AUTOSAR XML (schema 4-0-3)
package /ComponentTypes
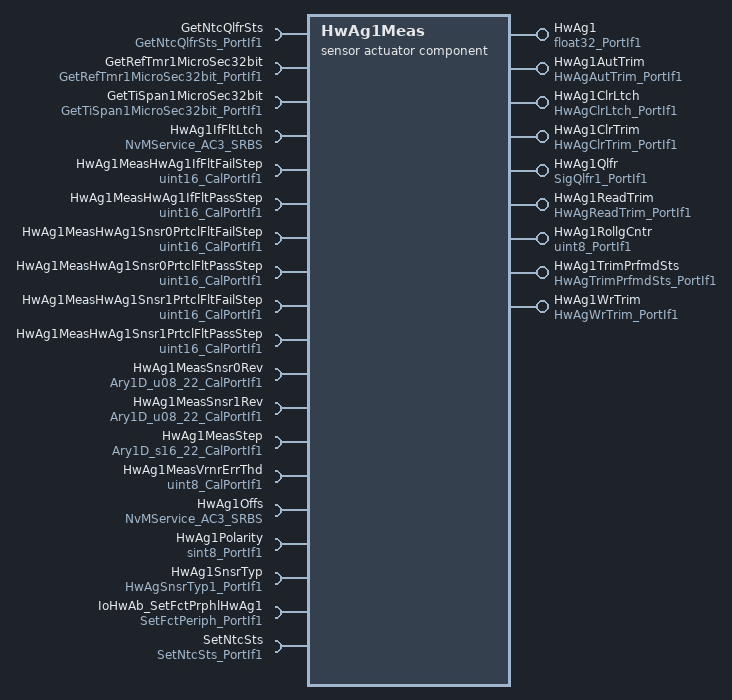
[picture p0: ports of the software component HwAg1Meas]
  sensor actuator sw component type HwAg1Meas
    9 x provide port:
      HwAg1: nonqueued-sender-com-spec{data-element=Val, init-value=0}, provided-interface=float32_PortIf1
      HwAg1AutTrim: server-com-spec{operation=Oper, queue-length=1}, provided-interface=HwAgAutTrim_PortIf1
      HwAg1ClrLtch: server-com-spec{operation=Oper, queue-length=1}, provided-interface=HwAgClrLtch_PortIf1
      HwAg1ClrTrim: server-com-spec{operation=Oper, queue-length=1}, provided-interface=HwAgClrTrim_PortIf1
      HwAg1Qlfr: nonqueued-sender-com-spec{data-element=Val, init-value=0}, provided-interface=SigQlfr1_PortIf1
      HwAg1ReadTrim: server-com-spec{operation=Oper, queue-length=1}, provided-interface=HwAgReadTrim_PortIf1
      HwAg1RollgCntr: nonqueued-sender-com-spec{data-element=Val, init-value=0}, provided-interface=uint8_PortIf1
      HwAg1TrimPrfmdSts: server-com-spec{operation=Oper, queue-length=1}, provided-interface=HwAgTrimPrfmdSts_PortIf1
      HwAg1WrTrim: server-com-spec{operation=Oper, queue-length=1}, provided-interface=HwAgWrTrim_PortIf1
    19 x require port:
      GetNtcQlfrSts: client-com-spec=Oper, required-interface=GetNtcQlfrSts_PortIf1
      GetRefTmr1MicroSec32bit: client-com-spec=Oper, required-interface=GetRefTmr1MicroSec32bit_PortIf1
      GetTiSpan1MicroSec32bit: client-com-spec=Oper, required-interface=GetTiSpan1MicroSec32bit_PortIf1
      HwAg1IfFltLtch: required-com-specs=[EraseBlock, GetErrorStatus, InvalidateNvBlock, ReadBlock, SetRamBlockStatus, WriteBlock], required-interface=NvMService_AC3_SRBS
      HwAg1MeasHwAg1IfFltFailStep: parameter-require-com-spec{init-value=2521, parameter=Val}, required-interface=uint16_CalPortIf1
      HwAg1MeasHwAg1IfFltPassStep: parameter-require-com-spec{init-value=1000, parameter=Val}, required-interface=uint16_CalPortIf1
      HwAg1MeasHwAg1Snsr0PrtclFltFailStep: parameter-require-com-spec{init-value=2521, parameter=Val}, required-interface=uint16_CalPortIf1
      HwAg1MeasHwAg1Snsr0PrtclFltPassStep: parameter-require-com-spec{init-value=1000, parameter=Val}, required-interface=uint16_CalPortIf1
      HwAg1MeasHwAg1Snsr1PrtclFltFailStep: parameter-require-com-spec{init-value=2521, parameter=Val}, required-interface=uint16_CalPortIf1
      HwAg1MeasHwAg1Snsr1PrtclFltPassStep: parameter-require-com-spec{init-value=1000, parameter=Val}, required-interface=uint16_CalPortIf1
      HwAg1MeasSnsr0Rev: parameter-require-com-spec{init-value=[0, 1, 1, 2, 2, 3, 3, 4, 4, 5, 5, 6, 6, 7, 7, 8, 8, 9, 9, 10, 10, 0], parameter=Ary1D}, required-interface=Ary1D_u08_22_CalPortIf1
      HwAg1MeasSnsr1Rev: parameter-require-com-spec{init-value=[0, 0, 1, 1, 2, 2, 3, 3, 4, 4, 5, 5, 6, 6, 7, 7, 8, 8, 9, 9, 10, 10], parameter=Ary1D}, required-interface=Ary1D_u08_22_CalPortIf1
      HwAg1MeasStep: parameter-require-com-spec{init-value=[0, -360, 36, -324, 72, -288, 108, -252, 144, -216, 180, -180, 216, -144, 252, -108, 288, -72, 324, -36, 360, -396], parameter=Ary1D}, required-interface=Ary1D_s16_22_CalPortIf1
      HwAg1MeasVrnrErrThd: parameter-require-com-spec{init-value=8, parameter=Val}, required-interface=uint8_CalPortIf1
      HwAg1Offs: required-com-specs=[EraseBlock, GetErrorStatus, InvalidateNvBlock, ReadBlock, SetRamBlockStatus, WriteBlock], required-interface=NvMService_AC3_SRBS
      HwAg1Polarity: nonqueued-receiver-com-spec{data-element=Val, filter=data-filter-type=ALWAYS, init-value=1}, required-interface=sint8_PortIf1
      HwAg1SnsrTyp: nonqueued-receiver-com-spec{data-element=Val, filter=data-filter-type=ALWAYS, init-value=0}, required-interface=HwAgSnsrTyp1_PortIf1
      IoHwAb_SetFctPrphlHwAg1: client-com-spec=Oper, required-interface=SetFctPeriph_PortIf1
      SetNtcSts: client-com-spec=Oper, required-interface=SetNtcSts_PortIf1
    behavior HwAg1Meas_InternalBehavior: data-type-mapping=Nexteer
      ar-typed-per-instance-memorys:
        31 x data, all with sw-calibration-access=READ-ONLY:
          dHwAg1MeasSnsr0Abs: type=float32
          dHwAg1MeasSnsr0CS: type=uint32
          dHwAg1MeasSnsr0FRXD: type=uint32
          dHwAg1MeasSnsr0Rel: type=float32
          dHwAg1MeasSnsr1Abs: type=float32
          dHwAg1MeasSnsr1CS: type=uint32
          dHwAg1MeasSnsr1FRXD: type=uint32
          dHwAg1MeasSnsr1Rel: type=float32
          HwAg1IfFltLtch: type=Boolean
          HwAg1InitStepSeqNrCmpl: type=boolean
          HwAg1LtchClr: type=boolean
          HwAg1Offs: type=HwAgOffsRec1
          HwAg1PrevHwAg1: type=float32
          HwAg1PrevRollCnt: type=uint8
          HwAg1PrevStepSeqNr: type=uint8
          HwAg1RawDataAvlStrtTi: type=uint32
          HwAg1Snsr0ComStsErrCntr: type=uint8
          HwAg1Snsr0IdErrCntr: type=uint8
          HwAg1Snsr0IntSnsrErrCntr: type=uint8
          HwAg1Snsr0NoMsgErrCntr: type=uint8
          HwAg1Snsr1ComStsErrCntr: type=uint8
          HwAg1Snsr1IdErrCntr: type=uint8
          HwAg1Snsr1IntSnsrErrCntr: type=uint8
          HwAg1Snsr1NoMsgErrCntr: type=uint8
          HwAg1SnsrTrigNr: type=uint8
          PrevHwAg1: type=float32
          PrevHwAg1Qlfr: type=SigQlfr1
          PrevHwAg1Snsr0Raw: type=uint16
          PrevHwAg1Snsr0TestOk: type=uint8
          PrevHwAg1Snsr1Raw: type=uint16
          PrevHwAg1Snsr1TestOk: type=uint8
      operation invoked event OIT_HwAg1AutTrim_Oper_HwAg1AutTrim_Oper: start-on-event=HwAg1AutTrim_Oper, operation=HwAg1AutTrim.Oper
      operation invoked event OIT_HwAg1ClrLtch_Oper_HwAg1ClrLtch_Oper: start-on-event=HwAg1ClrLtch_Oper, operation=HwAg1ClrLtch.Oper
      operation invoked event OIT_HwAg1ClrTrim_Oper_HwAg1ClrTrim_Oper: start-on-event=HwAg1ClrTrim_Oper, operation=HwAg1ClrTrim.Oper
      6 x timing event:
        HwAg1MeasInit1_InitEvent: start-on-event=HwAg1MeasInit1, period=0
        TMT_HwAg1MeasPer{1..4}: start-on-event=HwAg1MeasPer{1..4}, period=0.002
        TMT_HwAg1MeasPer5: start-on-event=HwAg1MeasPer5, period=0.1
      operation invoked event OIT_HwAg1ReadTrim_Oper_HwAg1ReadTrim_Oper: start-on-event=HwAg1ReadTrim_Oper, operation=HwAg1ReadTrim.Oper
      operation invoked event OIT_HwAg1TrimPrfmdSts_Oper_HwAg1TrimPrfmdSts_Oper: start-on-event=HwAg1TrimPrfmdSts_Oper, operation=HwAg1TrimPrfmdSts.Oper
      operation invoked event OIT_HwAg1WrTrim_Oper_HwAg1WrTrim_Oper: start-on-event=HwAg1WrTrim_Oper, operation=HwAg1WrTrim.Oper
      explicit-inter-runnable-variables:
        4 x data, all with init-value=0:
          HwAg1Snsr0Raw: type=uint16
          HwAg1Snsr0TestOk: type=uint8
          HwAg1Snsr1Raw: type=uint16
          HwAg1Snsr1TestOk: type=uint8
      port-api-options:
        enable-take-address=false, indirect-api=false, port=GetNtcQlfrSts
        enable-take-address=false, indirect-api=false, port=GetRefTmr1MicroSec32bit
        enable-take-address=false, indirect-api=false, port=GetTiSpan1MicroSec32bit
        enable-take-address=false, indirect-api=false, port=HwAg1
        enable-take-address=false, indirect-api=false, port=HwAg1AutTrim
        enable-take-address=false, indirect-api=false, port=HwAg1ClrLtch
        enable-take-address=false, indirect-api=false, port=HwAg1ClrTrim
        enable-take-address=false, indirect-api=false, port=HwAg1IfFltLtch
        enable-take-address=false, indirect-api=false, port=HwAg1MeasHwAg1IfFltFailStep
        enable-take-address=false, indirect-api=false, port=HwAg1MeasHwAg1IfFltPassStep
        enable-take-address=false, indirect-api=false, port=HwAg1MeasHwAg1Snsr0PrtclFltFailStep
        enable-take-address=false, indirect-api=false, port=HwAg1MeasHwAg1Snsr0PrtclFltPassStep
        enable-take-address=false, indirect-api=false, port=HwAg1MeasHwAg1Snsr1PrtclFltFailStep
        enable-take-address=false, indirect-api=false, port=HwAg1MeasHwAg1Snsr1PrtclFltPassStep
        enable-take-address=false, indirect-api=false, port=HwAg1MeasSnsr0Rev
        enable-take-address=false, indirect-api=false, port=HwAg1MeasSnsr1Rev
        enable-take-address=false, indirect-api=false, port=HwAg1MeasStep
        enable-take-address=false, indirect-api=false, port=HwAg1Offs
        enable-take-address=false, indirect-api=false, port=HwAg1Polarity
        enable-take-address=false, indirect-api=false, port=HwAg1ReadTrim
        enable-take-address=false, indirect-api=false, port=HwAg1SnsrTyp
        enable-take-address=false, indirect-api=false, port=HwAg1TrimPrfmdSts
        enable-take-address=false, indirect-api=false, port=HwAg1WrTrim
        enable-take-address=false, indirect-api=false, port=IoHwAb_SetFctPrphlHwAg1
        enable-take-address=false, indirect-api=false, port=SetNtcSts
      12 x runnable:
        HwAg1AutTrim_Oper
          sync call SC_HwAg1Offs_SetRamBlockStatus: operation=HwAg1Offs.SetRamBlockStatus, timeout=0
        HwAg1ClrLtch_Oper
          sync call SC_HwAg1IfFltLtch_SetRamBlockStatus: operation=HwAg1IfFltLtch.SetRamBlockStatus, timeout=0
        HwAg1ClrTrim_Oper
          sync call SC_HwAg1Offs_SetRamBlockStatus: operation=HwAg1Offs.SetRamBlockStatus, timeout=0
        HwAg1MeasInit1
          data-receive-point-by-arguments:
            access REC_HwAg1SnsrTyp_Val: accessed-variable=HwAg1SnsrTyp.Val
          7 x sync call, all with timeout=0:
            SC_GetRefTmr1MicroSec32bit_Oper: operation=GetRefTmr1MicroSec32bit.Oper
            SC_GetTiSpan1MicroSec32bit_Oper: operation=GetTiSpan1MicroSec32bit.Oper
            SC_HwAg1IfFltLtch_GetErrorStatus: operation=HwAg1IfFltLtch.GetErrorStatus
            SC_HwAg1IfFltLtch_SetRamBlockStatus: operation=HwAg1IfFltLtch.SetRamBlockStatus
            SC_HwAg1Offs_GetErrorStatus: operation=HwAg1Offs.GetErrorStatus
            SC_HwAg1Offs_SetRamBlockStatus: operation=HwAg1Offs.SetRamBlockStatus
            SC_IoHwAb_SetFctPrphlHwAg1_Oper: operation=IoHwAb_SetFctPrphlHwAg1.Oper
        HwAg1MeasPer1
          sync call SC_GetRefTmr1MicroSec32bit_Oper: operation=GetRefTmr1MicroSec32bit.Oper, timeout=0
          sync call SC_GetTiSpan1MicroSec32bit_Oper: operation=GetTiSpan1MicroSec32bit.Oper, timeout=0
        HwAg1MeasPer2
          data-receive-point-by-arguments:
            access REC_HwAg1SnsrTyp_Val: accessed-variable=HwAg1SnsrTyp.Val
          sync call SC_GetTiSpan1MicroSec32bit_Oper: operation=GetTiSpan1MicroSec32bit.Oper, timeout=0
          sync call SC_SetNtcSts_Oper: operation=SetNtcSts.Oper, timeout=0
          written-local-variables:
            access WRITE_HwAg1Snsr0Raw: accessed-variable=HwAg1Snsr0Raw
            access WRITE_HwAg1Snsr0TestOk: accessed-variable=HwAg1Snsr0TestOk
        HwAg1MeasPer3
          data-receive-point-by-arguments:
            access REC_HwAg1SnsrTyp_Val: accessed-variable=HwAg1SnsrTyp.Val
          sync call SC_GetRefTmr1MicroSec32bit_Oper: operation=GetRefTmr1MicroSec32bit.Oper, timeout=0
          sync call SC_GetTiSpan1MicroSec32bit_Oper: operation=GetTiSpan1MicroSec32bit.Oper, timeout=0
          sync call SC_SetNtcSts_Oper: operation=SetNtcSts.Oper, timeout=0
          written-local-variables:
            access WRITE_HwAg1Snsr1Raw: accessed-variable=HwAg1Snsr1Raw
            access WRITE_HwAg1Snsr1TestOk: accessed-variable=HwAg1Snsr1TestOk
        HwAg1MeasPer4
          data-receive-point-by-arguments:
            access REC_HwAg1Polarity_Val: accessed-variable=HwAg1Polarity.Val
            access REC_HwAg1SnsrTyp_Val: accessed-variable=HwAg1SnsrTyp.Val
          data-send-points:
            access SEND_HwAg1_Val: accessed-variable=HwAg1.Val
            access SEND_HwAg1Qlfr_Val: accessed-variable=HwAg1Qlfr.Val
            access SEND_HwAg1RollgCntr_Val: accessed-variable=HwAg1RollgCntr.Val
          read-local-variables:
            4 x access:
              READ_HwAg1Snsr0Raw: accessed-variable=HwAg1Snsr0Raw
              READ_HwAg1Snsr0TestOk: accessed-variable=HwAg1Snsr0TestOk
              READ_HwAg1Snsr1Raw: accessed-variable=HwAg1Snsr1Raw
              READ_HwAg1Snsr1TestOk: accessed-variable=HwAg1Snsr1TestOk
          sync call SC_GetNtcQlfrSts_Oper: operation=GetNtcQlfrSts.Oper, timeout=0
          sync call SC_SetNtcSts_Oper: operation=SetNtcSts.Oper, timeout=0
        HwAg1MeasPer5
          sync call SC_SetNtcSts_Oper: operation=SetNtcSts.Oper, timeout=0
        HwAg1ReadTrim_Oper
        HwAg1TrimPrfmdSts_Oper
        HwAg1WrTrim_Oper
          sync call SC_HwAg1Offs_SetRamBlockStatus: operation=HwAg1Offs.SetRamBlockStatus, timeout=0
      swc service dependency NvmHwAg1IfFltLtch: assigned-datas=role-based-data-assignment={role=ramBlock, used-data-element=HwAg1IfFltLtch}, assigned-ports=role-based-port-assignment={port-prototype=HwAg1IfFltLtch, role=NvMService_AC3_SRBS}
        service-needs:
          nv block needs NvmHwAg1IfFltLtch: n-data-sets=0, reliability=ERROR-DETECTION, resistant-to-changed-sw=true, restore-at-start=true, store-at-shutdown=true
      swc service dependency NvmHwAg1Offs: assigned-datas=role-based-data-assignment={role=ramBlock, used-data-element=HwAg1Offs}, assigned-ports=role-based-port-assignment={port-prototype=HwAg1Offs, role=NvMService_AC3_SRBS}
        service-needs:
          nv block needs NvmHwAg1Offs: n-data-sets=0, readonly=false, reliability=ERROR-DETECTION, resistant-to-changed-sw=true, restore-at-start=true, store-at-shutdown=true, write-only-once=false, writing-frequency=0, writing-priority=LOW
  swc implementation HwAg1Meas_Implementation: behavior=HwAg1Meas_InternalBehavior
    code-descriptors:
      code Default: artifact-descriptors=autosar-engineering-object={short-label=Default, category=SWSRC}
